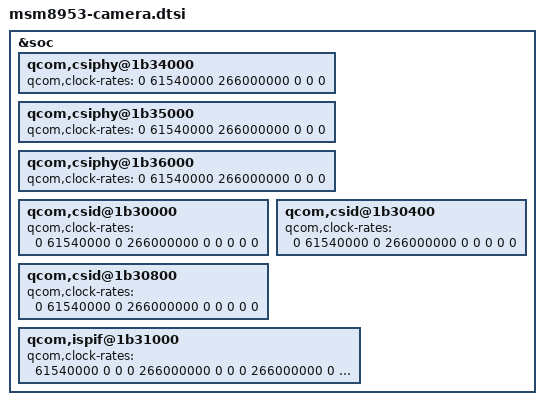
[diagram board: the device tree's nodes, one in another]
/*
 * Copyright (c) 2015-2016, The Linux Foundation. All rights reserved.
 *
 * This program is free software; you can redistribute it and/or modify
 * it under the terms of the GNU General Public License version 2 and
 * only version 2 as published by the Free Software Foundation.
 *
 * This program is distributed in the hope that it will be useful,
 * but WITHOUT ANY WARRANTY; without even the implied warranty of
 * MERCHANTABILITY or FITNESS FOR A PARTICULAR PURPOSE.  See the
 * GNU General Public License for more details.
 */

&soc {
	qcom,csiphy@1b34000 {
		qcom,clock-rates = <0 61540000 266000000 0 0 0>;
	};

	qcom,csiphy@1b35000 {
		qcom,clock-rates = <0 61540000 266000000 0 0 0>;
	};

	qcom,csiphy@1b36000 {
		qcom,clock-rates = <0 61540000 266000000 0 0 0>;
	};

	qcom,csid@1b30000  {
		qcom,clock-rates = <0 61540000 0 266000000 0 0 0 0 0>;
	};

	qcom,csid@1b30400 {
		qcom,clock-rates = <0 61540000 0 266000000 0 0 0 0 0>;
	};

	qcom,csid@1b30800 {
		qcom,clock-rates = <0 61540000 0 266000000 0 0 0 0 0>;
	};

	qcom,ispif@1b31000 {
		qcom,clock-rates = <61540000 0 0 0
			266000000 0 0 0
			266000000 0 0 0
			266000000 0 0 0
			0 0 0
			0 0 0>;
	};




};

